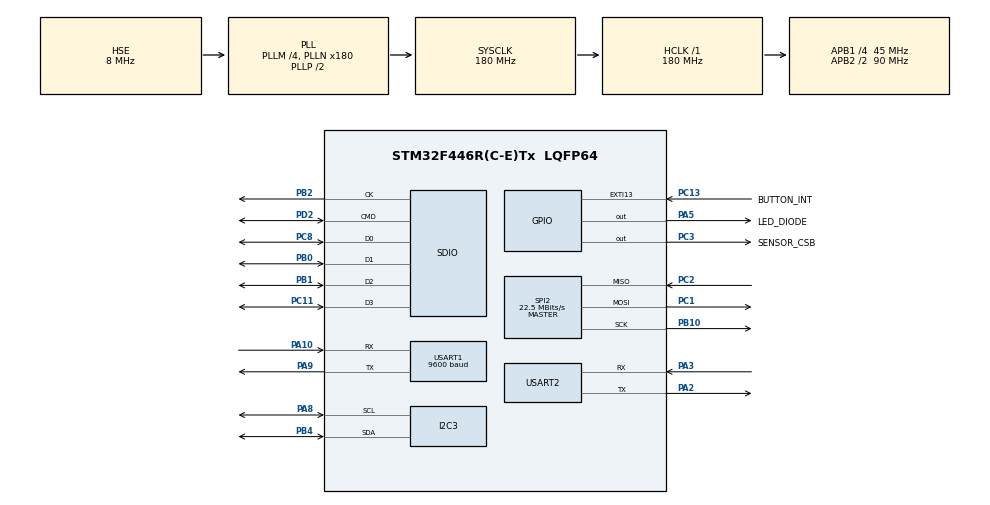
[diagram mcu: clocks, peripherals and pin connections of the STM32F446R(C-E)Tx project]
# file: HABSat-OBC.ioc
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Dma.Request0=USART1_RX
Dma.Request1=SDIO_RX
Dma.Request2=SDIO_TX
Dma.Request3=USART1_TX
Dma.Request4=USART2_RX
Dma.Request5=USART2_TX
Dma.SDIO_RX.1.Direction=DMA_PERIPH_TO_MEMORY
Dma.SDIO_RX.1.FIFOMode=DMA_FIFOMODE_ENABLE
Dma.SDIO_RX.1.FIFOThreshold=DMA_FIFO_THRESHOLD_FULL
Dma.SDIO_RX.1.Instance=DMA2_Stream3
Dma.SDIO_RX.1.MemBurst=DMA_MBURST_INC4
Dma.SDIO_RX.1.MemDataAlignment=DMA_MDATAALIGN_WORD
Dma.SDIO_RX.1.MemInc=DMA_MINC_ENABLE
Dma.SDIO_RX.1.Mode=DMA_PFCTRL
Dma.SDIO_RX.1.PeriphBurst=DMA_PBURST_INC4
Dma.SDIO_RX.1.PeriphDataAlignment=DMA_PDATAALIGN_WORD
Dma.SDIO_RX.1.PeriphInc=DMA_PINC_DISABLE
Dma.SDIO_RX.1.Priority=DMA_PRIORITY_LOW
Dma.SDIO_TX.2.Direction=DMA_MEMORY_TO_PERIPH
Dma.SDIO_TX.2.FIFOMode=DMA_FIFOMODE_ENABLE
Dma.SDIO_TX.2.FIFOThreshold=DMA_FIFO_THRESHOLD_FULL
Dma.SDIO_TX.2.Instance=DMA2_Stream6
Dma.SDIO_TX.2.MemBurst=DMA_MBURST_INC4
Dma.SDIO_TX.2.MemDataAlignment=DMA_MDATAALIGN_WORD
Dma.SDIO_TX.2.MemInc=DMA_MINC_ENABLE
Dma.SDIO_TX.2.Mode=DMA_PFCTRL
Dma.SDIO_TX.2.PeriphBurst=DMA_PBURST_INC4
Dma.SDIO_TX.2.PeriphDataAlignment=DMA_PDATAALIGN_WORD
Dma.SDIO_TX.2.PeriphInc=DMA_PINC_DISABLE
Dma.SDIO_TX.2.Priority=DMA_PRIORITY_LOW
Dma.USART1_RX.0.Direction=DMA_PERIPH_TO_MEMORY
Dma.USART1_RX.0.FIFOMode=DMA_FIFOMODE_DISABLE
Dma.USART1_RX.0.Instance=DMA2_Stream2
Dma.USART1_RX.0.MemDataAlignment=DMA_MDATAALIGN_BYTE
Dma.USART1_RX.0.MemInc=DMA_MINC_ENABLE
Dma.USART1_RX.0.Mode=DMA_CIRCULAR
Dma.USART1_RX.0.PeriphDataAlignment=DMA_PDATAALIGN_BYTE
Dma.USART1_RX.0.PeriphInc=DMA_PINC_DISABLE
Dma.USART1_RX.0.Priority=DMA_PRIORITY_MEDIUM
Dma.USART1_TX.3.Direction=DMA_MEMORY_TO_PERIPH
Dma.USART1_TX.3.FIFOMode=DMA_FIFOMODE_DISABLE
Dma.USART1_TX.3.Instance=DMA2_Stream7
Dma.USART1_TX.3.MemDataAlignment=DMA_MDATAALIGN_BYTE
Dma.USART1_TX.3.MemInc=DMA_MINC_ENABLE
Dma.USART1_TX.3.Mode=DMA_CIRCULAR
Dma.USART1_TX.3.PeriphDataAlignment=DMA_PDATAALIGN_BYTE
Dma.USART1_TX.3.PeriphInc=DMA_PINC_DISABLE
Dma.USART1_TX.3.Priority=DMA_PRIORITY_LOW
Dma.USART2_RX.4.Direction=DMA_PERIPH_TO_MEMORY
Dma.USART2_RX.4.FIFOMode=DMA_FIFOMODE_DISABLE
Dma.USART2_RX.4.Instance=DMA1_Stream5
Dma.USART2_RX.4.MemDataAlignment=DMA_MDATAALIGN_BYTE
Dma.USART2_RX.4.MemInc=DMA_MINC_ENABLE
Dma.USART2_RX.4.Mode=DMA_NORMAL
Dma.USART2_RX.4.PeriphDataAlignment=DMA_PDATAALIGN_BYTE
Dma.USART2_RX.4.PeriphInc=DMA_PINC_DISABLE
Dma.USART2_RX.4.Priority=DMA_PRIORITY_LOW
Dma.USART2_TX.5.Direction=DMA_MEMORY_TO_PERIPH
Dma.USART2_TX.5.FIFOMode=DMA_FIFOMODE_DISABLE
Dma.USART2_TX.5.Instance=DMA1_Stream6
Dma.USART2_TX.5.MemDataAlignment=DMA_MDATAALIGN_BYTE
Dma.USART2_TX.5.MemInc=DMA_MINC_ENABLE
Dma.USART2_TX.5.Mode=DMA_NORMAL
Dma.USART2_TX.5.PeriphDataAlignment=DMA_PDATAALIGN_BYTE
Dma.USART2_TX.5.PeriphInc=DMA_PINC_DISABLE
Dma.USART2_TX.5.Priority=DMA_PRIORITY_LOW
FATFS.USE_DMA_CODE_SD=1
FATFS._MAX_SS=4096
FATFS._USE_LFN=1
Mcu.Family=STM32F4
Mcu.Name=STM32F446R(C-E)Tx
Mcu.Package=LQFP64
NVIC.DMA1_Stream5_IRQn=true\:0\:0\:false\:false\:true\:false\:true
NVIC.DMA1_Stream6_IRQn=true\:0\:0\:false\:false\:true\:false\:true
NVIC.DMA2_Stream2_IRQn=true\:0\:0\:false\:false\:true\:false\:true
NVIC.DMA2_Stream3_IRQn=true\:0\:0\:false\:false\:true\:false\:true
NVIC.DMA2_Stream6_IRQn=true\:0\:0\:false\:false\:true\:false\:true
NVIC.DMA2_Stream7_IRQn=true\:0\:0\:false\:false\:true\:false\:true
NVIC.EXTI15_10_IRQn=true\:6\:0\:true\:false\:true\:true\:true
NVIC.PriorityGroup=NVIC_PRIORITYGROUP_4
NVIC.SDIO_IRQn=true\:0\:0\:false\:false\:true\:true\:true
NVIC.TIM6_DAC_IRQn=true\:0\:0\:false\:false\:true\:false\:true
NVIC.TimeBase=TIM6_DAC_IRQn
NVIC.TimeBaseIP=TIM6
NVIC.USART1_IRQn=true\:0\:0\:false\:false\:true\:true\:true
NVIC.USART2_IRQn=true\:0\:0\:false\:false\:true\:true\:true
PA10.Mode=Asynchronous
PA10.Signal=USART1_RX
PA13.Mode=Serial_Wire
PA13.Signal=SYS_JTMS-SWDIO
PA14.Mode=Serial_Wire
PA14.Signal=SYS_JTCK-SWCLK
PA2.Mode=Asynchronous
PA2.Signal=USART2_TX
PA3.Mode=Asynchronous
PA3.Signal=USART2_RX
PA5.GPIO_Label=LED_DIODE
PA5.Signal=GPIO_Output
PA8.Mode=I2C
PA8.Signal=I2C3_SCL
PA9.Mode=Asynchronous
PA9.Signal=USART1_TX
PB0.Mode=SD_4_bits_Wide_bus
PB0.Signal=SDIO_D1
PB1.Mode=SD_4_bits_Wide_bus
PB1.Signal=SDIO_D2
PB10.Mode=Full_Duplex_Master
PB10.Signal=SPI2_SCK
PB2.Mode=SD_4_bits_Wide_bus
PB2.Signal=SDIO_CK
PB4.Mode=I2C
PB4.Signal=I2C3_SDA
PC1.Mode=Full_Duplex_Master
PC1.Signal=SPI2_MOSI
PC11.Mode=SD_4_bits_Wide_bus
PC11.Signal=SDIO_D3
PC13.GPIO_Label=BUTTON_INT
PC13.GPIO_ModeDefaultEXTI=GPIO_MODE_IT_FALLING
PC13.Signal=GPXTI13
PC2.Mode=Full_Duplex_Master
PC2.Signal=SPI2_MISO
PC3.GPIO_Label=SENSOR_CSB
PC3.Signal=GPIO_Output
PC8.Mode=SD_4_bits_Wide_bus
PC8.Signal=SDIO_D0
PD2.Mode=SD_4_bits_Wide_bus
PD2.Signal=SDIO_CMD
PH0-OSC_IN.Mode=HSE-External-Oscillator
PH0-OSC_IN.Signal=RCC_OSC_IN
PH1-OSC_OUT.Mode=HSE-External-Oscillator
PH1-OSC_OUT.Signal=RCC_OSC_OUT
ProjectManager.HeapSize=0x200
ProjectManager.StackSize=0x400
ProjectManager.TargetToolchain=STM32CubeIDE
RCC.AHBFreq_Value=180000000
RCC.APB1CLKDivider=RCC_HCLK_DIV4
RCC.APB1Freq_Value=45000000
RCC.APB1TimFreq_Value=90000000
RCC.APB2CLKDivider=RCC_HCLK_DIV2
RCC.APB2Freq_Value=90000000
RCC.APB2TimFreq_Value=180000000
RCC.CortexFreq_Value=180000000
RCC.HCLKFreq_Value=180000000
RCC.HSE_VALUE=8000000
RCC.PLLM=4
RCC.PLLN=180
RCC.PLLQ=8
RCC.PLLSAIM=8
RCC.PLLSAIP=RCC_PLLSAIP_DIV4
RCC.PLLSourceVirtual=RCC_PLLSOURCE_HSE
RCC.SYSCLKFreq_VALUE=180000000
RCC.SYSCLKSource=RCC_SYSCLKSOURCE_PLLCLK
RCC.USBCLockSelection=RCC_CLK48CLKSOURCE_PLLSAIP
RCC.USBFreq_Value=48000000
RCC.VCOOutputFreq_Value=360000000
SPI2.CalculateBaudRate=22.5 MBits/s
SPI2.Direction=SPI_DIRECTION_2LINES
SPI2.Mode=SPI_MODE_MASTER
SPI2.VirtualType=VM_MASTER
USART1.BaudRate=9600
USART1.VirtualMode=VM_ASYNC
USART2.VirtualMode=VM_ASYNC
VP_FATFS_VS_SDIO.Mode=SDIO
VP_SYS_VS_tim6.Mode=TIM6
board=custom

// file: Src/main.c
/* USER CODE BEGIN Header */
/**
  ******************************************************************************
  * @file           : main.c
  * @brief          : Main program body
  ******************************************************************************
  * @attention
  *
  * <h2><center>&copy; Copyright (c) 2020 STMicroelectronics.
  * All rights reserved.</center></h2>
  *
  * This software component is licensed by ST under Ultimate Liberty license
  * SLA0044, the "License"; You may not use this file except in compliance with
  * the License. You may obtain a copy of the License at:
  *                             www.st.com/SLA0044
  *
  ******************************************************************************
  */
/* USER CODE END Header */
#include "main.h"
#include "fatfs.h"

/* USER CODE BEGIN Includes */
#include "main_loop.hpp"

/* USER CODE END Includes */

I2C_HandleTypeDef hi2c3;

SD_HandleTypeDef hsd;
DMA_HandleTypeDef hdma_sdio_rx;
DMA_HandleTypeDef hdma_sdio_tx;

SPI_HandleTypeDef hspi2;

UART_HandleTypeDef huart1;
UART_HandleTypeDef huart2;
DMA_HandleTypeDef hdma_usart1_rx;
DMA_HandleTypeDef hdma_usart1_tx;
DMA_HandleTypeDef hdma_usart2_rx;
DMA_HandleTypeDef hdma_usart2_tx;

void SystemClock_Config(void);
static void MX_GPIO_Init(void);
static void MX_DMA_Init(void);
static void MX_USART1_UART_Init(void);
static void MX_I2C3_Init(void);
static void MX_SPI2_Init(void);
static void MX_SDIO_SD_Init(void);
static void MX_USART2_UART_Init(void);

int main(void)
{

  /* MCU Configuration--------------------------------------------------------*/

  /* Reset of all peripherals, Initializes the Flash interface and the Systick. */
  HAL_Init();

  /* Configure the system clock */
  SystemClock_Config();

  /* Initialize all configured peripherals */
  MX_GPIO_Init();
  MX_DMA_Init();
  MX_USART1_UART_Init();
  MX_I2C3_Init();
  MX_SPI2_Init();
  MX_SDIO_SD_Init();
  MX_FATFS_Init();
  MX_USART2_UART_Init();

  /* Infinite loop */
  /* USER CODE BEGIN WHILE */

  mainLoop();
    /* USER CODE END WHILE */

}

void SystemClock_Config(void)
{
  RCC_OscInitTypeDef RCC_OscInitStruct = {0};
  RCC_ClkInitTypeDef RCC_ClkInitStruct = {0};
  RCC_PeriphCLKInitTypeDef PeriphClkInitStruct = {0};

  /** Configure the main internal regulator output voltage
  */
  __HAL_RCC_PWR_CLK_ENABLE();
  __HAL_PWR_VOLTAGESCALING_CONFIG(PWR_REGULATOR_VOLTAGE_SCALE1);
  /** Initializes the RCC Oscillators according to the specified parameters
  * in the RCC_OscInitTypeDef structure.
  */
  RCC_OscInitStruct.OscillatorType = RCC_OSCILLATORTYPE_HSE;
  RCC_OscInitStruct.HSEState = RCC_HSE_ON;
  RCC_OscInitStruct.PLL.PLLState = RCC_PLL_ON;
  RCC_OscInitStruct.PLL.PLLSource = RCC_PLLSOURCE_HSE;
  RCC_OscInitStruct.PLL.PLLM = 4;
  RCC_OscInitStruct.PLL.PLLN = 180;
  RCC_OscInitStruct.PLL.PLLP = RCC_PLLP_DIV2;
  RCC_OscInitStruct.PLL.PLLQ = 8;
  RCC_OscInitStruct.PLL.PLLR = 2;
  if (HAL_RCC_OscConfig(&RCC_OscInitStruct) != HAL_OK)
  {
    Error_Handler();
  }
  /** Activate the Over-Drive mode
  */
  if (HAL_PWREx_EnableOverDrive() != HAL_OK)
  {
    Error_Handler();
  }
  /** Initializes the CPU, AHB and APB buses clocks
  */
  RCC_ClkInitStruct.ClockType = RCC_CLOCKTYPE_HCLK|RCC_CLOCKTYPE_SYSCLK
                              |RCC_CLOCKTYPE_PCLK1|RCC_CLOCKTYPE_PCLK2;
  RCC_ClkInitStruct.SYSCLKSource = RCC_SYSCLKSOURCE_PLLCLK;
  RCC_ClkInitStruct.AHBCLKDivider = RCC_SYSCLK_DIV1;
  RCC_ClkInitStruct.APB1CLKDivider = RCC_HCLK_DIV4;
  RCC_ClkInitStruct.APB2CLKDivider = RCC_HCLK_DIV2;

  if (HAL_RCC_ClockConfig(&RCC_ClkInitStruct, FLASH_LATENCY_5) != HAL_OK)
  {
    Error_Handler();
  }
  PeriphClkInitStruct.PeriphClockSelection = RCC_PERIPHCLK_SDIO|RCC_PERIPHCLK_CLK48;
  PeriphClkInitStruct.PLLSAI.PLLSAIM = 8;
  PeriphClkInitStruct.PLLSAI.PLLSAIN = 192;
  PeriphClkInitStruct.PLLSAI.PLLSAIQ = 2;
  PeriphClkInitStruct.PLLSAI.PLLSAIP = RCC_PLLSAIP_DIV4;
  PeriphClkInitStruct.PLLSAIDivQ = 1;
  PeriphClkInitStruct.Clk48ClockSelection = RCC_CLK48CLKSOURCE_PLLSAIP;
  PeriphClkInitStruct.SdioClockSelection = RCC_SDIOCLKSOURCE_CLK48;
  if (HAL_RCCEx_PeriphCLKConfig(&PeriphClkInitStruct) != HAL_OK)
  {
    Error_Handler();
  }
}

static void MX_I2C3_Init(void)
{

  hi2c3.Instance = I2C3;
  hi2c3.Init.ClockSpeed = 100000;
  hi2c3.Init.DutyCycle = I2C_DUTYCYCLE_2;
  hi2c3.Init.OwnAddress1 = 0;
  hi2c3.Init.AddressingMode = I2C_ADDRESSINGMODE_7BIT;
  hi2c3.Init.DualAddressMode = I2C_DUALADDRESS_DISABLE;
  hi2c3.Init.OwnAddress2 = 0;
  hi2c3.Init.GeneralCallMode = I2C_GENERALCALL_DISABLE;
  hi2c3.Init.NoStretchMode = I2C_NOSTRETCH_DISABLE;
  if (HAL_I2C_Init(&hi2c3) != HAL_OK)
  {
    Error_Handler();
  }

}

static void MX_SDIO_SD_Init(void)
{

  hsd.Instance = SDIO;
  hsd.Init.ClockEdge = SDIO_CLOCK_EDGE_RISING;
  hsd.Init.ClockBypass = SDIO_CLOCK_BYPASS_DISABLE;
  hsd.Init.ClockPowerSave = SDIO_CLOCK_POWER_SAVE_DISABLE;
  hsd.Init.BusWide = SDIO_BUS_WIDE_1B;
  hsd.Init.HardwareFlowControl = SDIO_HARDWARE_FLOW_CONTROL_DISABLE;
  hsd.Init.ClockDiv = 0;

}

static void MX_SPI2_Init(void)
{

  /* SPI2 parameter configuration*/
  hspi2.Instance = SPI2;
  hspi2.Init.Mode = SPI_MODE_MASTER;
  hspi2.Init.Direction = SPI_DIRECTION_2LINES;
  hspi2.Init.DataSize = SPI_DATASIZE_8BIT;
  hspi2.Init.CLKPolarity = SPI_POLARITY_LOW;
  hspi2.Init.CLKPhase = SPI_PHASE_1EDGE;
  hspi2.Init.NSS = SPI_NSS_SOFT;
  hspi2.Init.BaudRatePrescaler = SPI_BAUDRATEPRESCALER_2;
  hspi2.Init.FirstBit = SPI_FIRSTBIT_MSB;
  hspi2.Init.TIMode = SPI_TIMODE_DISABLE;
  hspi2.Init.CRCCalculation = SPI_CRCCALCULATION_DISABLE;
  hspi2.Init.CRCPolynomial = 10;
  if (HAL_SPI_Init(&hspi2) != HAL_OK)
  {
    Error_Handler();
  }

}

static void MX_USART1_UART_Init(void)
{

  huart1.Instance = USART1;
  huart1.Init.BaudRate = 9600;
  huart1.Init.WordLength = UART_WORDLENGTH_8B;
  huart1.Init.StopBits = UART_STOPBITS_1;
  huart1.Init.Parity = UART_PARITY_NONE;
  huart1.Init.Mode = UART_MODE_TX_RX;
  huart1.Init.HwFlowCtl = UART_HWCONTROL_NONE;
  huart1.Init.OverSampling = UART_OVERSAMPLING_16;
  if (HAL_UART_Init(&huart1) != HAL_OK)
  {
    Error_Handler();
  }

}

static void MX_USART2_UART_Init(void)
{

  huart2.Instance = USART2;
  huart2.Init.BaudRate = 115200;
  huart2.Init.WordLength = UART_WORDLENGTH_8B;
  huart2.Init.StopBits = UART_STOPBITS_1;
  huart2.Init.Parity = UART_PARITY_NONE;
  huart2.Init.Mode = UART_MODE_TX_RX;
  huart2.Init.HwFlowCtl = UART_HWCONTROL_NONE;
  huart2.Init.OverSampling = UART_OVERSAMPLING_16;
  if (HAL_UART_Init(&huart2) != HAL_OK)
  {
    Error_Handler();
  }

}

static void MX_DMA_Init(void)
{

  /* DMA controller clock enable */
  __HAL_RCC_DMA2_CLK_ENABLE();
  __HAL_RCC_DMA1_CLK_ENABLE();

  /* DMA interrupt init */
  /* DMA1_Stream5_IRQn interrupt configuration */
  HAL_NVIC_SetPriority(DMA1_Stream5_IRQn, 0, 0);
  HAL_NVIC_EnableIRQ(DMA1_Stream5_IRQn);
  /* DMA1_Stream6_IRQn interrupt configuration */
  HAL_NVIC_SetPriority(DMA1_Stream6_IRQn, 0, 0);
  HAL_NVIC_EnableIRQ(DMA1_Stream6_IRQn);
  /* DMA2_Stream2_IRQn interrupt configuration */
  HAL_NVIC_SetPriority(DMA2_Stream2_IRQn, 0, 0);
  HAL_NVIC_EnableIRQ(DMA2_Stream2_IRQn);
  /* DMA2_Stream3_IRQn interrupt configuration */
  HAL_NVIC_SetPriority(DMA2_Stream3_IRQn, 0, 0);
  HAL_NVIC_EnableIRQ(DMA2_Stream3_IRQn);
  /* DMA2_Stream6_IRQn interrupt configuration */
  HAL_NVIC_SetPriority(DMA2_Stream6_IRQn, 0, 0);
  HAL_NVIC_EnableIRQ(DMA2_Stream6_IRQn);
  /* DMA2_Stream7_IRQn interrupt configuration */
  HAL_NVIC_SetPriority(DMA2_Stream7_IRQn, 0, 0);
  HAL_NVIC_EnableIRQ(DMA2_Stream7_IRQn);

}

static void MX_GPIO_Init(void)
{
  GPIO_InitTypeDef GPIO_InitStruct = {0};

  /* GPIO Ports Clock Enable */
  __HAL_RCC_GPIOC_CLK_ENABLE();
  __HAL_RCC_GPIOH_CLK_ENABLE();
  __HAL_RCC_GPIOA_CLK_ENABLE();
  __HAL_RCC_GPIOB_CLK_ENABLE();
  __HAL_RCC_GPIOD_CLK_ENABLE();

  /*Configure GPIO pin Output Level */
  HAL_GPIO_WritePin(SENSOR_CSB_GPIO_Port, SENSOR_CSB_Pin, GPIO_PIN_RESET);

  /*Configure GPIO pin Output Level */
  HAL_GPIO_WritePin(LED_DIODE_GPIO_Port, LED_DIODE_Pin, GPIO_PIN_RESET);

  /*Configure GPIO pin : BUTTON_INT_Pin */
  GPIO_InitStruct.Pin = BUTTON_INT_Pin;
  GPIO_InitStruct.Mode = GPIO_MODE_IT_FALLING;
  GPIO_InitStruct.Pull = GPIO_NOPULL;
  HAL_GPIO_Init(BUTTON_INT_GPIO_Port, &GPIO_InitStruct);

  /*Configure GPIO pin : SENSOR_CSB_Pin */
  GPIO_InitStruct.Pin = SENSOR_CSB_Pin;
  GPIO_InitStruct.Mode = GPIO_MODE_OUTPUT_PP;
  GPIO_InitStruct.Pull = GPIO_NOPULL;
  GPIO_InitStruct.Speed = GPIO_SPEED_FREQ_LOW;
  HAL_GPIO_Init(SENSOR_CSB_GPIO_Port, &GPIO_InitStruct);

  /*Configure GPIO pin : LED_DIODE_Pin */
  GPIO_InitStruct.Pin = LED_DIODE_Pin;
  GPIO_InitStruct.Mode = GPIO_MODE_OUTPUT_PP;
  GPIO_InitStruct.Pull = GPIO_NOPULL;
  GPIO_InitStruct.Speed = GPIO_SPEED_FREQ_LOW;
  HAL_GPIO_Init(LED_DIODE_GPIO_Port, &GPIO_InitStruct);

  /* EXTI interrupt init*/
  HAL_NVIC_SetPriority(EXTI15_10_IRQn, 6, 0);
  HAL_NVIC_EnableIRQ(EXTI15_10_IRQn);

}

 /**
  * @brief  Period elapsed callback in non blocking mode
  * @note   This function is called  when TIM6 interrupt took place, inside
  * HAL_TIM_IRQHandler(). It makes a direct call to HAL_IncTick() to increment
  * a global variable "uwTick" used as application time base.
  * @param  htim : TIM handle
  * @retval None
  */
void HAL_TIM_PeriodElapsedCallback(TIM_HandleTypeDef *htim)
{
  if (htim->Instance == TIM6) {
    HAL_IncTick();
  }
}

void Error_Handler(void)
{
}

/************************ (C) COPYRIGHT STMicroelectronics *****END OF FILE****/
